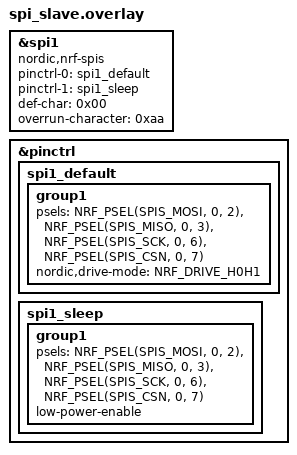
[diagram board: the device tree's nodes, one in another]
// To get started, press Ctrl+Space to bring up the completion menu and view the available nodes.

// You can also use the buttons in the sidebar to perform actions on nodes.
// Actions currently available include:

// * Enabling / disabling the node
// * Adding the bus to a bus
// * Removing the node
// * Connecting ADC channels

// For more help, browse the DeviceTree documentation at https://docs.zephyrproject.org/latest/guides/dts/index.html
// You can also visit the nRF DeviceTree extension documentation at https://docs.nordicsemi.com/bundle/nrf-connect-vscode/page/guides/ncs_configure_app.html#devicetree-support-in-the-extension

spi_slave:  &spi1 {
	status = "okay";
	compatible = "nordic,nrf-spis";
	pinctrl-0 = <&spi1_default>;
	pinctrl-1 = <&spi1_sleep>;
	pinctrl-names = "default", "sleep";
	def-char = <0x00>;
	overrun-character = <0xaa>;
};

&pinctrl {
	spi1_default: spi1_default {
		group1 {
			psels = <NRF_PSEL(SPIS_MOSI, 0, 2)>,
				<NRF_PSEL(SPIS_MISO, 0, 3)>,
				<NRF_PSEL(SPIS_SCK, 0, 6)>,
				<NRF_PSEL(SPIS_CSN, 0, 7)>;
				nordic,drive-mode = <NRF_DRIVE_H0H1>;
		};
	};
	spi1_sleep: spi1_sleep {
		group1 {
			psels = <NRF_PSEL(SPIS_MOSI, 0, 2)>,
				<NRF_PSEL(SPIS_MISO, 0, 3)>,
				<NRF_PSEL(SPIS_SCK, 0, 6)>,
				<NRF_PSEL(SPIS_CSN, 0, 7)>;
			low-power-enable;
		};
	};
};

